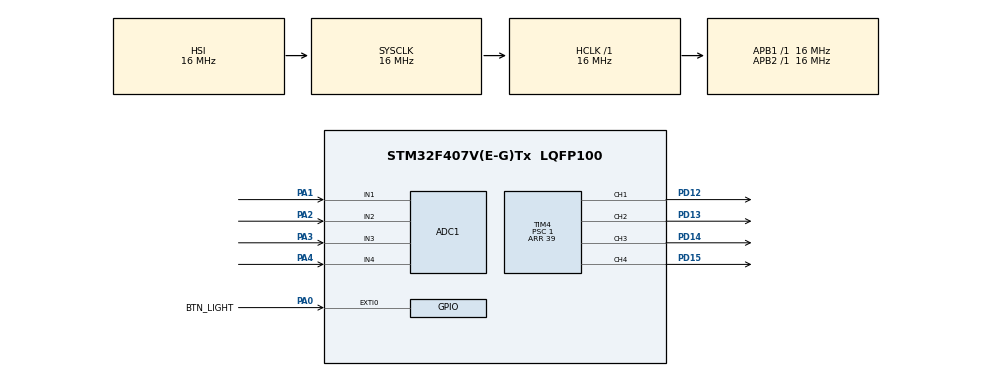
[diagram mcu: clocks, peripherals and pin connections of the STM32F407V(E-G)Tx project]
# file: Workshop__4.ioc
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ADC1.Channel-3\#ChannelRegularConversion=ADC_CHANNEL_1
ADC1.ClockPrescaler=ADC_CLOCK_SYNC_PCLK_DIV8
ADC1.NbrOfConversionFlag=1
ADC1.Rank-3\#ChannelRegularConversion=1
ADC1.SamplingTime-3\#ChannelRegularConversion=ADC_SAMPLETIME_480CYCLES
ADC1.master=1
Mcu.Family=STM32F4
Mcu.Name=STM32F407V(E-G)Tx
Mcu.Package=LQFP100
NVIC.ADC_IRQn=true\:0\:0\:false\:false\:true\:true\:true\:true
NVIC.EXTI0_IRQn=true\:0\:0\:false\:false\:true\:true\:true\:true
NVIC.PriorityGroup=NVIC_PRIORITYGROUP_4
PA0-WKUP.GPIO_Label=BTN_LIGHT
PA0-WKUP.Signal=GPXTI0
PA1.Signal=ADCx_IN1
PA2.Signal=ADCx_IN2
PA3.Signal=ADCx_IN3
PA4.Signal=ADCx_IN4
PD12.Signal=S_TIM4_CH1
PD13.Signal=S_TIM4_CH2
PD14.Signal=S_TIM4_CH3
PD15.Signal=S_TIM4_CH4
PH0-OSC_IN.Mode=HSE-External-Oscillator
PH0-OSC_IN.Signal=RCC_OSC_IN
PH1-OSC_OUT.Mode=HSE-External-Oscillator
PH1-OSC_OUT.Signal=RCC_OSC_OUT
ProjectManager.HeapSize=0x200
ProjectManager.StackSize=0x400
ProjectManager.TargetToolchain=STM32CubeIDE
RCC.48MHZClocksFreq_Value=48000000
RCC.AHBFreq_Value=16000000
RCC.APB1Freq_Value=16000000
RCC.APB1TimFreq_Value=16000000
RCC.APB2Freq_Value=16000000
RCC.APB2TimFreq_Value=16000000
RCC.CortexFreq_Value=16000000
RCC.HCLKFreq_Value=16000000
RCC.HSE_VALUE=8000000
RCC.HSI_VALUE=16000000
RCC.LSE_VALUE=32768
RCC.SYSCLKFreq_VALUE=16000000
RCC.VCOOutputFreq_Value=192000000
SH.ADCx_IN1.0=ADC1_IN1,IN1
SH.ADCx_IN2.0=ADC1_IN2,IN2
SH.ADCx_IN3.0=ADC1_IN3,IN3
SH.ADCx_IN4.0=ADC1_IN4,IN4
SH.S_TIM4_CH1.0=TIM4_CH1,PWM Generation1 CH1
SH.S_TIM4_CH2.0=TIM4_CH2,PWM Generation2 CH2
SH.S_TIM4_CH3.0=TIM4_CH3,PWM Generation3 CH3
SH.S_TIM4_CH4.0=TIM4_CH4,PWM Generation4 CH4
TIM4.AutoReloadPreload=TIM_AUTORELOAD_PRELOAD_ENABLE
TIM4.Channel-PWM\ Generation1\ CH1=TIM_CHANNEL_1
TIM4.Channel-PWM\ Generation2\ CH2=TIM_CHANNEL_2
TIM4.Channel-PWM\ Generation3\ CH3=TIM_CHANNEL_3
TIM4.Channel-PWM\ Generation4\ CH4=TIM_CHANNEL_4
TIM4.CounterMode=TIM_COUNTERMODE_DOWN
TIM4.Period=39
TIM4.Prescaler=1
VP_TIM4_VS_ClockSourceINT.Mode=Internal
board=custom

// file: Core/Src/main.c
/* USER CODE BEGIN Header */
/**
  ******************************************************************************
  * @file           : main.c
  * @brief          : Main program body
  ******************************************************************************
  * @attention
  *
  * Copyright (c) 2024 STMicroelectronics.
  * All rights reserved.
  *
  * This software is licensed under terms that can be found in the LICENSE file
  * in the root directory of this software component.
  * If no LICENSE file comes with this software, it is provided AS-IS.
  *
  ******************************************************************************
  */
/* USER CODE END Header */
#include "main.h"

ADC_HandleTypeDef hadc1;

TIM_HandleTypeDef htim4;

/* USER CODE BEGIN PV */
ADC_ChannelConfTypeDef sConfig = {0};
/* USER CODE END PV */

void SystemClock_Config(void);
static void MX_GPIO_Init(void);
static void MX_ADC1_Init(void);
static void MX_TIM4_Init(void);

int main(void)
{

  /* MCU Configuration--------------------------------------------------------*/

  /* Reset of all peripherals, Initializes the Flash interface and the Systick. */
  HAL_Init();

  /* Configure the system clock */
  SystemClock_Config();

  /* Initialize all configured peripherals */
  MX_GPIO_Init();
  MX_ADC1_Init();
  MX_TIM4_Init();
  /* USER CODE BEGIN 2 */
  HAL_TIM_PWM_Start(&htim4, TIM_CHANNEL_1);
  HAL_TIM_PWM_Start(&htim4, TIM_CHANNEL_2);
  HAL_TIM_PWM_Start(&htim4, TIM_CHANNEL_3);
  HAL_TIM_PWM_Start(&htim4, TIM_CHANNEL_4);
  /* USER CODE END 2 */

  /* Infinite loop */
  /* USER CODE BEGIN WHILE */
  HAL_ADC_Start_IT(&hadc1);
  while (1)
  {
    /* USER CODE END WHILE */

  }
}

void SystemClock_Config(void)
{
  RCC_OscInitTypeDef RCC_OscInitStruct = {0};
  RCC_ClkInitTypeDef RCC_ClkInitStruct = {0};

  /** Configure the main internal regulator output voltage
  */
  __HAL_RCC_PWR_CLK_ENABLE();
  __HAL_PWR_VOLTAGESCALING_CONFIG(PWR_REGULATOR_VOLTAGE_SCALE1);

  /** Initializes the RCC Oscillators according to the specified parameters
  * in the RCC_OscInitTypeDef structure.
  */
  RCC_OscInitStruct.OscillatorType = RCC_OSCILLATORTYPE_HSI;
  RCC_OscInitStruct.HSIState = RCC_HSI_ON;
  RCC_OscInitStruct.HSICalibrationValue = RCC_HSICALIBRATION_DEFAULT;
  RCC_OscInitStruct.PLL.PLLState = RCC_PLL_NONE;
  if (HAL_RCC_OscConfig(&RCC_OscInitStruct) != HAL_OK)
  {
    Error_Handler();
  }

  /** Initializes the CPU, AHB and APB buses clocks
  */
  RCC_ClkInitStruct.ClockType = RCC_CLOCKTYPE_HCLK|RCC_CLOCKTYPE_SYSCLK
                              |RCC_CLOCKTYPE_PCLK1|RCC_CLOCKTYPE_PCLK2;
  RCC_ClkInitStruct.SYSCLKSource = RCC_SYSCLKSOURCE_HSI;
  RCC_ClkInitStruct.AHBCLKDivider = RCC_SYSCLK_DIV1;
  RCC_ClkInitStruct.APB1CLKDivider = RCC_HCLK_DIV1;
  RCC_ClkInitStruct.APB2CLKDivider = RCC_HCLK_DIV1;

  if (HAL_RCC_ClockConfig(&RCC_ClkInitStruct, FLASH_LATENCY_0) != HAL_OK)
  {
    Error_Handler();
  }
}

static void MX_ADC1_Init(void)
{

  /** Configure the global features of the ADC (Clock, Resolution, Data Alignment and number of conversion)
  */
  hadc1.Instance = ADC1;
  hadc1.Init.ClockPrescaler = ADC_CLOCK_SYNC_PCLK_DIV8;
  hadc1.Init.Resolution = ADC_RESOLUTION_12B;
  hadc1.Init.ScanConvMode = DISABLE;
  hadc1.Init.ContinuousConvMode = DISABLE;
  hadc1.Init.DiscontinuousConvMode = DISABLE;
  hadc1.Init.ExternalTrigConvEdge = ADC_EXTERNALTRIGCONVEDGE_NONE;
  hadc1.Init.ExternalTrigConv = ADC_SOFTWARE_START;
  hadc1.Init.DataAlign = ADC_DATAALIGN_RIGHT;
  hadc1.Init.NbrOfConversion = 1;
  hadc1.Init.DMAContinuousRequests = DISABLE;
  hadc1.Init.EOCSelection = ADC_EOC_SINGLE_CONV;
  if (HAL_ADC_Init(&hadc1) != HAL_OK)
  {
    Error_Handler();
  }

  /** Configure for the selected ADC regular channel its corresponding rank in the sequencer and its sample time.
  */
  sConfig.Channel = ADC_CHANNEL_1;
  sConfig.Rank = 1;
  sConfig.SamplingTime = ADC_SAMPLETIME_480CYCLES;
  if (HAL_ADC_ConfigChannel(&hadc1, &sConfig) != HAL_OK)
  {
    Error_Handler();
  }

}

static void MX_TIM4_Init(void)
{

  TIM_ClockConfigTypeDef sClockSourceConfig = {0};
  TIM_MasterConfigTypeDef sMasterConfig = {0};
  TIM_OC_InitTypeDef sConfigOC = {0};

  htim4.Instance = TIM4;
  htim4.Init.Prescaler = 1;
  htim4.Init.CounterMode = TIM_COUNTERMODE_DOWN;
  htim4.Init.Period = 39;
  htim4.Init.ClockDivision = TIM_CLOCKDIVISION_DIV1;
  htim4.Init.AutoReloadPreload = TIM_AUTORELOAD_PRELOAD_ENABLE;
  if (HAL_TIM_Base_Init(&htim4) != HAL_OK)
  {
    Error_Handler();
  }
  sClockSourceConfig.ClockSource = TIM_CLOCKSOURCE_INTERNAL;
  if (HAL_TIM_ConfigClockSource(&htim4, &sClockSourceConfig) != HAL_OK)
  {
    Error_Handler();
  }
  if (HAL_TIM_PWM_Init(&htim4) != HAL_OK)
  {
    Error_Handler();
  }
  sMasterConfig.MasterOutputTrigger = TIM_TRGO_RESET;
  sMasterConfig.MasterSlaveMode = TIM_MASTERSLAVEMODE_DISABLE;
  if (HAL_TIMEx_MasterConfigSynchronization(&htim4, &sMasterConfig) != HAL_OK)
  {
    Error_Handler();
  }
  sConfigOC.OCMode = TIM_OCMODE_PWM1;
  sConfigOC.Pulse = 0;
  sConfigOC.OCPolarity = TIM_OCPOLARITY_HIGH;
  sConfigOC.OCFastMode = TIM_OCFAST_DISABLE;
  if (HAL_TIM_PWM_ConfigChannel(&htim4, &sConfigOC, TIM_CHANNEL_1) != HAL_OK)
  {
    Error_Handler();
  }
  if (HAL_TIM_PWM_ConfigChannel(&htim4, &sConfigOC, TIM_CHANNEL_2) != HAL_OK)
  {
    Error_Handler();
  }
  if (HAL_TIM_PWM_ConfigChannel(&htim4, &sConfigOC, TIM_CHANNEL_3) != HAL_OK)
  {
    Error_Handler();
  }
  if (HAL_TIM_PWM_ConfigChannel(&htim4, &sConfigOC, TIM_CHANNEL_4) != HAL_OK)
  {
    Error_Handler();
  }
  HAL_TIM_MspPostInit(&htim4);

}

static void MX_GPIO_Init(void)
{
  GPIO_InitTypeDef GPIO_InitStruct = {0};

  /* GPIO Ports Clock Enable */
  __HAL_RCC_GPIOH_CLK_ENABLE();
  __HAL_RCC_GPIOA_CLK_ENABLE();
  __HAL_RCC_GPIOD_CLK_ENABLE();

  /*Configure GPIO pin : BTN_LIGHT_Pin */
  GPIO_InitStruct.Pin = BTN_LIGHT_Pin;
  GPIO_InitStruct.Mode = GPIO_MODE_IT_RISING;
  GPIO_InitStruct.Pull = GPIO_NOPULL;
  HAL_GPIO_Init(BTN_LIGHT_GPIO_Port, &GPIO_InitStruct);

  /* EXTI interrupt init*/
  HAL_NVIC_SetPriority(EXTI0_IRQn, 0, 0);
  HAL_NVIC_EnableIRQ(EXTI0_IRQn);

}

void Error_Handler(void)
{
  __disable_irq();
  while (1)
  {
  }
}
